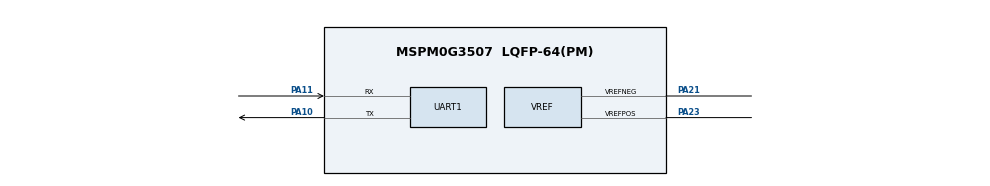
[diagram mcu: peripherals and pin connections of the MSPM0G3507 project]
//@cliArgs --device "MSPM0G350X" --package "LQFP-64(PM)" --part "Default"
//@v2CliArgs --device "MSPM0G3507" --package "LQFP-64(PM)"
// @cliArgs --board /ti/boards/LP_MSPM0G3507 --rtos nortos

/**
 * Import the modules used in this configuration.
 */
const ADC12         = scripting.addModule("/ti/driverlib/ADC12", {}, false);
const ADC121        = ADC12.addInstance();
const ADC122        = ADC12.addInstance();
const Board         = scripting.addModule("/ti/driverlib/Board");
const DMA           = scripting.addModule("/ti/driverlib/DMA");
const GPIO          = scripting.addModule("/ti/driverlib/GPIO", {}, false);
const GPIO1         = GPIO.addInstance();
const MATHACL       = scripting.addModule("/ti/driverlib/MATHACL");
const SYSCTL        = scripting.addModule("/ti/driverlib/SYSCTL");
const TIMER         = scripting.addModule("/ti/driverlib/TIMER", {}, false);
const TIMER1        = TIMER.addInstance();
const TIMER2        = TIMER.addInstance();
const UART          = scripting.addModule("/ti/driverlib/UART", {}, false);
const UART1         = UART.addInstance();
const VREF          = scripting.addModule("/ti/driverlib/VREF");
const ProjectConfig = scripting.addModule("/ti/project_config/ProjectConfig");

/**
 * Write custom configuration values to the imported modules.
 */
const divider7       = system.clockTree["PLL_PDIV"];
divider7.divideValue = 2;

const divider9       = system.clockTree["UDIV"];
divider9.divideValue = 2;

const multiplier2         = system.clockTree["PLL_QDIV"];
multiplier2.multiplyValue = 5;

const mux8       = system.clockTree["HSCLKMUX"];
mux8.inputSelect = "HSCLKMUX_SYSPLL2X";

ADC121.$name                 = "ADC12_0";
ADC121.trigSrc               = "DL_ADC12_TRIG_SRC_EVENT";
ADC121.subChanID             = 1;
ADC121.sampCnt               = 1;
ADC121.enabledDMATriggers    = ["DL_ADC12_DMA_MEM0_RESULT_LOADED"];
ADC121.powerDownMode         = "DL_ADC12_POWER_DOWN_MODE_MANUAL";
ADC121.interruptPriority     = "1";
ADC121.adcMem0trig           = "DL_ADC12_TRIGGER_MODE_TRIGGER_NEXT";
ADC121.repeatMode            = true;
ADC121.adcMem0vref           = "VREF";
ADC121.adcMem1vref           = "VREF";
ADC121.adcMem0avgen          = true;
ADC121.adcMem1avgen          = true;
ADC121.sampClkSrc            = "DL_ADC12_CLOCK_ULPCLK";
ADC121.endAdd                = 1;
ADC121.enabledInterrupts     = ["DL_ADC12_INTERRUPT_MEM0_RESULT_LOADED","DL_ADC12_INTERRUPT_MEM1_RESULT_LOADED"];
ADC121.samplingOperationMode = "sequence";
ADC121.sampleTime0           = "280ns";
ADC121.adcMem1chansel        = "DL_ADC12_INPUT_CHAN_7";
ADC121.hwNumerator           = "DL_ADC12_HW_AVG_NUM_ACC_8";
ADC121.hwDenominator         = "DL_ADC12_HW_AVG_DEN_DIV_BY_8";
ADC121.peripheral.$assign    = "ADC0";
ADC121.adcPin0Config.$name   = "ti_driverlib_gpio_GPIOPinGeneric6";
ADC121.adcPin7Config.$name   = "ti_driverlib_gpio_GPIOPinGeneric1";

ADC122.$name                 = "ADC12_1";
ADC122.powerDownMode         = "DL_ADC12_POWER_DOWN_MODE_MANUAL";
ADC122.subChanID             = 2;
ADC122.trigSrc               = "DL_ADC12_TRIG_SRC_EVENT";
ADC122.sampCnt               = 1;
ADC122.enabledDMATriggers    = ["DL_ADC12_DMA_MEM0_RESULT_LOADED"];
ADC122.interruptPriority     = "1";
ADC122.sampClkSrc            = "DL_ADC12_CLOCK_ULPCLK";
ADC122.adcMem0trig           = "DL_ADC12_TRIGGER_MODE_TRIGGER_NEXT";
ADC122.repeatMode            = true;
ADC122.adcMem0vref           = "VREF";
ADC122.adcMem1vref           = "VREF";
ADC122.adcMem0avgen          = true;
ADC122.adcMem1avgen          = true;
ADC122.endAdd                = 1;
ADC122.enabledInterrupts     = ["DL_ADC12_INTERRUPT_MEM0_RESULT_LOADED","DL_ADC12_INTERRUPT_MEM1_RESULT_LOADED"];
ADC122.samplingOperationMode = "sequence";
ADC122.sampleTime0           = "280ns";
ADC122.adcMem0chansel        = "DL_ADC12_INPUT_CHAN_1";
ADC122.hwNumerator           = "DL_ADC12_HW_AVG_NUM_ACC_8";
ADC122.hwDenominator         = "DL_ADC12_HW_AVG_DEN_DIV_BY_8";
ADC122.adcPin0Config.$name   = "ti_driverlib_gpio_GPIOPinGeneric7";
ADC122.adcPin1Config.$name   = "ti_driverlib_gpio_GPIOPinGeneric0";

GPIO1.$name                                 = "GPIO_RS485";
GPIO1.associatedPins.create(2);
GPIO1.associatedPins[0].$name               = "DIR";
GPIO1.associatedPins[0].assignedPort        = "PORTA";
GPIO1.associatedPins[0].subOutputPolicy     = "TOGGLE";
GPIO1.associatedPins[0].assignedPin         = "18";
GPIO1.associatedPins[1].$name               = "TERM";
GPIO1.associatedPins[1].initialValue        = "SET";
GPIO1.associatedPins[1].assignedPort        = "PORTA";
GPIO1.associatedPins[1].assignedPortSegment = "Lower";
GPIO1.associatedPins[1].assignedPin         = "4";

SYSCTL.forceDefaultClkConfig = true;
SYSCTL.clockTreeEn           = true;

TIMER1.event1ControllerInterruptEn = ["ZERO_EVENT"];
TIMER1.event2ControllerInterruptEn = ["ZERO_EVENT"];
TIMER1.timerMode                   = "PERIODIC";
TIMER1.$name                       = "TIMER_0_ADC";
TIMER1.event1PublisherChannel      = 1;
TIMER1.event2PublisherChannel      = 2;
TIMER1.timerPeriod                 = "31.25us";
TIMER1.peripheral.$assign          = "TIMG0";

TIMER2.timerMode                   = "PERIODIC";
TIMER2.repeatCounter               = 4;
TIMER2.$name                       = "TIMER_1_PosCal";
TIMER2.interrupts                  = ["ZERO"];
TIMER2.interruptPriority           = "2";
TIMER2.event1PublisherChannel      = 3;
TIMER2.event1ControllerInterruptEn = ["ZERO_EVENT"];
TIMER2.timerPeriod                 = "31.25us";
TIMER2.peripheral.$assign          = "TIMG6";

UART1.$name                      = "UART_0";
UART1.enabledDMARXTriggers       = "DL_UART_DMA_INTERRUPT_RX";
UART1.enabledDMATXTriggers       = "DL_UART_DMA_INTERRUPT_TX";
UART1.enabledInterrupts          = ["DMA_DONE_RX","DMA_DONE_TX","EOT_DONE","TX"];
UART1.interruptPriority          = "0";
UART1.targetBaudRate             = 2000000;
UART1.uartClkDiv                 = "2";
UART1.ovsRate                    = "8";
UART1.peripheral.rxPin.$assign   = "PA11";
UART1.peripheral.txPin.$assign   = "PA10";
UART1.DMA_CHANNEL_RX.srcLength   = "BYTE";
UART1.DMA_CHANNEL_RX.dstLength   = "BYTE";
UART1.DMA_CHANNEL_RX.$name       = "DMA_CH1";
UART1.DMA_CHANNEL_RX.addressMode = "f2b";
UART1.DMA_CHANNEL_TX.$name       = "DMA_CH0";
UART1.DMA_CHANNEL_TX.srcLength   = "BYTE";
UART1.DMA_CHANNEL_TX.dstLength   = "BYTE";
UART1.DMA_CHANNEL_TX.addressMode = "b2f";

VREF.basicExtVolt                  = 3.3;
VREF.basicIntVolt                  = "DL_VREF_BUFCONFIG_OUTPUT_2_5V";
VREF.basicMode                     = "DL_VREF_ENABLE_DISABLE";
VREF.basicVrefPins                 = "VREF+-";
VREF.peripheral.$assign            = "VREF";
VREF.peripheral.vrefPosPin.$assign = "PA23";
VREF.peripheral.vrefNegPin.$assign = "PA21";

ProjectConfig.genLibIQ        = true;
ProjectConfig.genLibIQVersion = "MATHACL";
